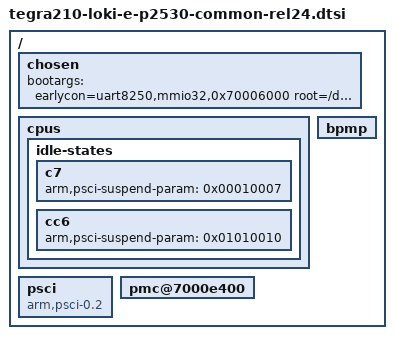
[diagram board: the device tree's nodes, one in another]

/ {
	chosen {
		bootargs = "earlycon=uart8250,mmio32,0x70006000 root=/dev/mmcblk0p19 skip_initramfs roottype=ext4 init=/init";
	};

	cpus {
		idle-states {
			c7 {
				arm,psci-suspend-param = <0x00010007>;
			};

			cc6 {
				arm,psci-suspend-param = <0x01010010>;
			};
		};
	};

	psci {
		compatible = "arm,psci-0.2";
	};

	bpmp {
		status = "okay";
	};

	pmc@7000e400 {
		/delete-property/ nvidia,secure-pmc;
	};
};
